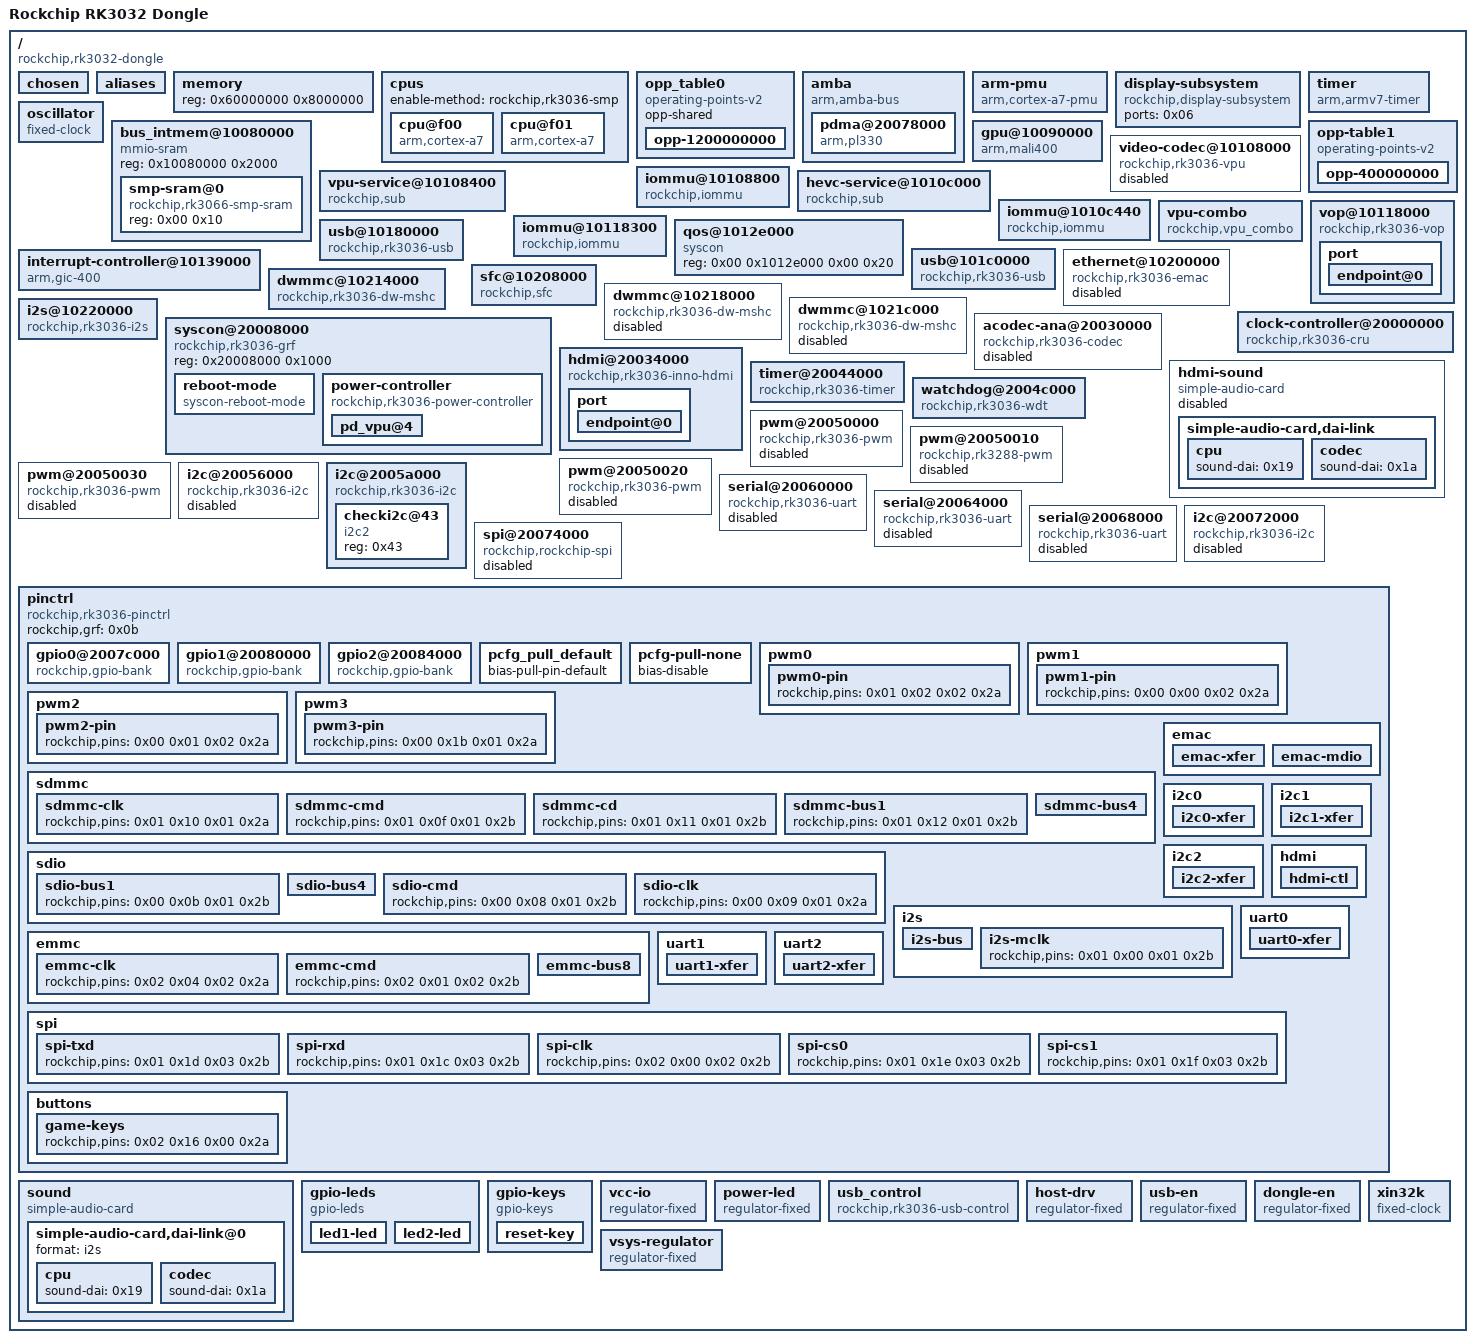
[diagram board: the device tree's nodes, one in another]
/dts-v1/;

/ {
	#address-cells = <0x01>;
	#size-cells = <0x01>;
	compatible = "rockchip,rk3032-dongle\0rockchip,rk3036";
	interrupt-parent = <0x01>;
	model = "Rockchip RK3032 Dongle";

	chosen {
		bootargs = "console=ttyS0,115200 rw root=PARTUUID=614e0000-0000 rootfstype=squashfs rootwait";
	};

	aliases {
		ethernet0 = "/ethernet@10200000";
		i2c0 = "/i2c@20072000";
		i2c1 = "/i2c@20056000";
		i2c2 = "/i2c@2005a000";
		mshc0 = "/dwmmc@1021c000";
		mshc1 = "/dwmmc@10214000";
		mshc2 = "/dwmmc@10218000";
		serial0 = "/serial@20060000";
		serial1 = "/serial@20064000";
		serial2 = "/serial@20068000";
		spi = "/spi@20074000";
	};

	memory {
		device_type = "memory";
		reg = <0x60000000 0x8000000>;
	};

	cpus {
		#address-cells = <0x01>;
		#size-cells = <0x00>;
		enable-method = "rockchip,rk3036-smp";

		cpu@f00 {
			device_type = "cpu";
			compatible = "arm,cortex-a7";
			reg = <0xf00>;
			resets = <0x02 0x00>;
			operating-points-v2 = <0x03>;
			clocks = <0x02 0x04>;
			phandle = <0x04>;
		};

		cpu@f01 {
			device_type = "cpu";
			compatible = "arm,cortex-a7";
			reg = <0xf01>;
			resets = <0x02 0x01>;
			operating-points-v2 = <0x03>;
			phandle = <0x05>;
		};
	};

	opp_table0 {
		compatible = "operating-points-v2";
		opp-shared;
		phandle = <0x03>;

		opp-1200000000 {
			opp-hz = <0x00 0x47868c00>;
			opp-microvolt = <0x12b128 0x12b128 0x12b128>;
			clock-latency-ns = <0x9c40>;
		};
	};

	amba {
		compatible = "arm,amba-bus";
		#address-cells = <0x01>;
		#size-cells = <0x01>;
		ranges;

		pdma@20078000 {
			compatible = "arm,pl330\0arm,primecell";
			reg = <0x20078000 0x4000>;
			interrupts = <0x00 0x00 0x04 0x00 0x01 0x04>;
			#dma-cells = <0x01>;
			arm,pl330-broken-no-flushp;
			peripherals-req-type-burst;
			clocks = <0x02 0xc2>;
			clock-names = "apb_pclk";
			phandle = <0x13>;
		};
	};

	arm-pmu {
		compatible = "arm,cortex-a7-pmu";
		interrupts = <0x00 0x4c 0x04 0x00 0x4d 0x04>;
		interrupt-affinity = <0x04 0x05>;
	};

	display-subsystem {
		compatible = "rockchip,display-subsystem";
		ports = <0x06>;
	};

	timer {
		compatible = "arm,armv7-timer";
		arm,cpu-registers-not-fw-configured;
		interrupts = <0x01 0x0d 0x304 0x01 0x0e 0x304 0x01 0x0b 0x304 0x01 0x0a 0x304>;
		clock-frequency = <0x16e3600>;
	};

	oscillator {
		compatible = "fixed-clock";
		clock-frequency = <0x16e3600>;
		clock-output-names = "xin24m";
		#clock-cells = <0x00>;
		phandle = <0x1b>;
	};

	bus_intmem@10080000 {
		compatible = "mmio-sram";
		reg = <0x10080000 0x2000>;
		#address-cells = <0x01>;
		#size-cells = <0x01>;
		ranges = <0x00 0x10080000 0x2000>;

		smp-sram@0 {
			compatible = "rockchip,rk3066-smp-sram";
			reg = <0x00 0x10>;
		};
	};

	gpu@10090000 {
		compatible = "arm,mali400";
		reg = <0x10091000 0x200 0x10090000 0x100 0x10093000 0x100 0x10098000 0x1100 0x10094000 0x100>;
		reg-names = "Mali_L2\0Mali_GP\0Mali_GP_MMU\0Mali_PP0\0Mali_PP0_MMU";
		interrupts = <0x00 0x03 0x04 0x00 0x04 0x04 0x00 0x05 0x04 0x00 0x04 0x04>;
		interrupt-names = "Mali_GP_IRQ\0Mali_GP_MMU_IRQ\0Mali_PP0_IRQ\0Mali_PP0_MMU_IRQ";
		clocks = <0x02 0x40>;
		clock-names = "clk_mali";
		assigned-clocks = <0x02 0x40>;
		assigned-clock-rates = <0x17d78400>;
		assigned-clock-parents = <0x02 0x02>;
		operating-points-v2 = <0x07>;
		status = "okay";
		phandle = <0x2f>;
	};

	opp-table1 {
		compatible = "operating-points-v2";
		phandle = <0x07>;

		opp-400000000 {
			opp-hz = <0x00 0x17d78400>;
			opp-microvolt = <0x10c8e0>;
		};
	};

	video-codec@10108000 {
		compatible = "rockchip,rk3036-vpu\0rockchip,rk3288-vpu";
		reg = <0x10108000 0x800>;
		interrupts = <0x00 0x06 0x04 0x00 0x07 0x04>;
		interrupt-names = "vepu\0vdpu";
		clocks = <0x02 0xd0 0x02 0x1dc>;
		clock-names = "aclk\0hclk";
		iommus = <0x08>;
		assigned-clocks = <0x02 0xd0>;
		assigned-clock-rates = <0x11b3dc40>;
		assigned-clock-parents = <0x02 0x03>;
		power-domains = <0x09 0x04>;
		status = "disabled";
		phandle = <0x30>;
	};

	vpu-service@10108400 {
		compatible = "rockchip,sub";
		reg = <0x10108400 0x400>;
		dev_mode = <0x00>;
		interrupts = <0x00 0x07 0x04>;
		interrupt-names = "irq_dec";
		iommus = <0x08>;
		allocator = <0x01>;
		power-domains = <0x09 0x04>;
		phandle = <0x0d>;
	};

	iommu@10108800 {
		compatible = "rockchip,iommu";
		reg = <0x10108800 0x100>;
		interrupts = <0x00 0x37 0x04>;
		interrupt-names = "vpu_mmu";
		#iommu-cells = <0x00>;
		power-domains = <0x09 0x04>;
		status = "okay";
		phandle = <0x08>;
	};

	hevc-service@1010c000 {
		compatible = "rockchip,sub";
		reg = <0x1010c000 0x400>;
		dev_mode = <0x01>;
		interrupts = <0x00 0x39 0x04>;
		interrupt-names = "irq_dec";
		allocator = <0x01>;
		iommus = <0x0a>;
		power-domains = <0x09 0x04>;
		phandle = <0x0c>;
	};

	iommu@1010c440 {
		compatible = "rockchip,iommu";
		reg = <0x1010c440 0x40 0x1010c480 0x40>;
		interrupts = <0x00 0x38 0x04>;
		interrupt-names = "hevc_mmu";
		#iommu-cells = <0x00>;
		power-domains = <0x09 0x04>;
		status = "okay";
		phandle = <0x0a>;
	};

	vpu-combo {
		compatible = "rockchip,vpu_combo";
		rockchip,grf = <0x0b>;
		subcnt = <0x02>;
		rockchip,sub = <0x0c 0x0d>;
		mode_bit = <0x03>;
		mode_ctrl = <0x144>;
		clocks = <0x02 0xd0 0x02 0x1dc 0x02 0xd3>;
		clock-names = "aclk_vcodec\0hclk_vcodec\0clk_core";
		assigned-clocks = <0x02 0xd0>;
		assigned-clock-rates = <0x11b3dc40>;
		assigned-clock-parents = <0x02 0x03>;
		resets = <0x02 0x70 0x02 0x71 0x02 0x73>;
		reset-names = "video_a\0video_h\0video";
		power-domains = <0x09 0x04>;
		status = "okay";
		phandle = <0x31>;
	};

	vop@10118000 {
		compatible = "rockchip,rk3036-vop";
		reg = <0x10118000 0x19c>;
		interrupts = <0x00 0x2b 0x04>;
		clocks = <0x02 0xc5 0x02 0x64 0x02 0x1d1>;
		clock-names = "aclk_vop\0dclk_vop\0hclk_vop";
		resets = <0x02 0x75 0x02 0x76 0x02 0x77>;
		reset-names = "axi\0ahb\0dclk";
		iommus = <0x0e>;
		status = "okay";
		phandle = <0x32>;

		port {
			#address-cells = <0x01>;
			#size-cells = <0x00>;
			phandle = <0x06>;

			endpoint@0 {
				reg = <0x00>;
				remote-endpoint = <0x0f>;
				phandle = <0x18>;
			};
		};
	};

	iommu@10118300 {
		compatible = "rockchip,iommu";
		reg = <0x10118300 0x100>;
		interrupts = <0x00 0x2b 0x04>;
		interrupt-names = "vop_mmu";
		#iommu-cells = <0x00>;
		status = "okay";
		phandle = <0x0e>;
	};

	qos@1012e000 {
		compatible = "syscon";
		reg = <0x00 0x1012e000 0x00 0x20>;
		phandle = <0x16>;
	};

	interrupt-controller@10139000 {
		compatible = "arm,gic-400";
		interrupt-controller;
		#interrupt-cells = <0x03>;
		#address-cells = <0x00>;
		reg = <0x10139000 0x1000 0x1013a000 0x2000 0x1013c000 0x2000 0x1013e000 0x2000>;
		interrupts = <0x01 0x09 0x304>;
		phandle = <0x01>;
	};

	usb@10180000 {
		compatible = "rockchip,rk3036-usb\0rockchip,rk3066-usb\0snps,dwc2";
		reg = <0x10180000 0x40000>;
		interrupts = <0x00 0x0a 0x04>;
		clocks = <0x02 0x1c1>;
		clock-names = "otg";
		dr_mode = "host";
		g-np-tx-fifo-size = <0x10>;
		g-rx-fifo-size = <0x118>;
		g-tx-fifo-size = <0x100 0x80 0x80 0x40 0x20 0x10>;
		g-use-dma;
		status = "okay";
		phandle = <0x33>;
	};

	usb@101c0000 {
		compatible = "rockchip,rk3036-usb\0rockchip,rk3066-usb\0snps,dwc2";
		reg = <0x101c0000 0x40000>;
		interrupts = <0x00 0x0b 0x04>;
		clocks = <0x02 0x1c2>;
		clock-names = "otg";
		dr_mode = "host";
		status = "okay";
		phandle = <0x34>;
	};

	ethernet@10200000 {
		compatible = "rockchip,rk3036-emac\0snps,arc-emac";
		reg = <0x10200000 0x4000>;
		interrupts = <0x00 0x08 0x04>;
		#address-cells = <0x01>;
		#size-cells = <0x00>;
		rockchip,grf = <0x0b>;
		clocks = <0x02 0x1cc 0x02 0x98 0x02 0x97>;
		clock-names = "hclk\0macref\0macclk";
		assigned-clocks = <0x02 0x99>;
		assigned-clock-parents = <0x02 0x02>;
		max-speed = <0x64>;
		phy-mode = "rmii";
		status = "disabled";
		phandle = <0x35>;
	};

	sfc@10208000 {
		compatible = "rockchip,sfc";
		reg = <0x10208000 0x200>;
		interrupts = <0x00 0x09 0x04>;
		clocks = <0x02 0xa0 0x02 0x1c6>;
		clock-names = "clk_sfc\0hclk_sfc";
		assigned-clocks = <0x02 0xa0>;
		assigned-clock-rates = <0x5f5e100>;
		status = "okay";
		phandle = <0x36>;
	};

	dwmmc@10214000 {
		compatible = "rockchip,rk3036-dw-mshc\0rockchip,rk3288-dw-mshc";
		reg = <0x10214000 0x4000>;
		interrupts = <0x00 0x0e 0x04>;
		#address-cells = <0x01>;
		#size-cells = <0x00>;
		pinctrl-names = "default";
		pinctrl-0 = <0x10 0x11 0x12>;
		clock-freq-min-max = <0x61a80 0x23c3460>;
		clocks = <0x02 0x1c8 0x02 0x44>;
		clock-names = "biu\0ciu";
		dmas = <0x13 0x0a>;
		dma-names = "rx-tx";
		num-slots = <0x01>;
		fifo-depth = <0x100>;
		bus-width = <0x04>;
		status = "okay";
		clock-frequency = <0x23c3460>;
		supports-highspeed;
		supports-sd;
		broken-cd;
		card-detect-delay = <0xc8>;
		ignore-pm-notify;
		keep-power-in-suspend;
		vmmc-supply = <0x14>;
		cd-gpios = <0x15 0x11 0x00>;
		phandle = <0x37>;
	};

	dwmmc@10218000 {
		compatible = "rockchip,rk3036-dw-mshc\0rockchip,rk3288-dw-mshc";
		reg = <0x10218000 0x4000>;
		clock-freq-min-max = <0x61a80 0x23c3460>;
		clocks = <0x02 0x1c9 0x02 0x45 0x02 0x73 0x02 0x77>;
		clock-names = "biu\0ciu\0ciu_drv\0ciu_sample";
		fifo-depth = <0x100>;
		interrupts = <0x00 0x0f 0x04>;
		status = "disabled";
		phandle = <0x38>;
	};

	dwmmc@1021c000 {
		compatible = "rockchip,rk3036-dw-mshc\0rockchip,rk3288-dw-mshc";
		reg = <0x1021c000 0x4000>;
		interrupts = <0x00 0x10 0x04>;
		bus-width = <0x08>;
		cap-mmc-highspeed;
		clock-frequency = <0x23c3460>;
		clock-freq-min-max = <0x61a80 0x23c3460>;
		clocks = <0x02 0x1cb 0x02 0x47 0x02 0x75 0x02 0x79>;
		clock-names = "biu\0ciu\0ciu_drv\0ciu_sample";
		default-sample-phase = <0x9e>;
		disable-wp;
		dmas = <0x13 0x0c>;
		dma-names = "rx-tx";
		fifo-depth = <0x100>;
		non-removable;
		num-slots = <0x01>;
		supports-emmc;
		status = "disabled";
		phandle = <0x39>;
	};

	i2s@10220000 {
		compatible = "rockchip,rk3036-i2s\0rockchip,rk3066-i2s";
		reg = <0x10220000 0x4000>;
		interrupts = <0x00 0x33 0x04>;
		#address-cells = <0x01>;
		#size-cells = <0x00>;
		clock-names = "i2s_clk\0i2s_hclk";
		clocks = <0x02 0x52 0x02 0x1ce>;
		assigned-clocks = <0x02 0x7f>;
		assigned-clock-parents = <0x02 0x7e>;
		dmas = <0x13 0x00 0x13 0x01>;
		dma-names = "tx\0rx";
		resets = <0x02 0x18>;
		reset-names = "reset-m";
		status = "okay";
		#sound-dai-cells = <0x00>;
		phandle = <0x19>;
	};

	clock-controller@20000000 {
		compatible = "rockchip,rk3036-cru";
		reg = <0x20000000 0x1000>;
		rockchip,grf = <0x0b>;
		#clock-cells = <0x01>;
		#reset-cells = <0x01>;
		assigned-clocks = <0x02 0x03>;
		assigned-clock-rates = <0x2367b880>;
		phandle = <0x02>;
	};

	syscon@20008000 {
		compatible = "rockchip,rk3036-grf\0syscon\0simple-mfd";
		reg = <0x20008000 0x1000>;
		phandle = <0x0b>;

		reboot-mode {
			compatible = "syscon-reboot-mode";
			offset = <0x1d8>;
			mode-normal = <0x5242c300>;
			mode-recovery = <0x5242c303>;
			mode-bootloader = <0x5242c309>;
			mode-loader = <0x5242c301>;
			mode-ums = <0x5242c30c>;
		};

		power-controller {
			compatible = "rockchip,rk3036-power-controller";
			#power-domain-cells = <0x01>;
			#address-cells = <0x01>;
			#size-cells = <0x00>;
			phandle = <0x09>;

			pd_vpu@4 {
				reg = <0x04>;
				clocks = <0x02 0xd0 0x02 0x1dc 0x02 0xd3>;
				pm_qos = <0x16>;
			};
		};
	};

	acodec-ana@20030000 {
		compatible = "rockchip,rk3036-codec";
		reg = <0x20030000 0x4000>;
		rockchip,grf = <0x0b>;
		clock-names = "acodec_pclk";
		clocks = <0x02 0x171>;
		#sound-dai-cells = <0x00>;
		status = "disabled";
		phandle = <0x3a>;
	};

	hdmi@20034000 {
		compatible = "rockchip,rk3036-inno-hdmi";
		reg = <0x20034000 0x4000>;
		interrupts = <0x00 0x2d 0x04>;
		clocks = <0x02 0xcb 0x02 0x168>;
		clock-names = "aclk\0pclk";
		rockchip,grf = <0x0b>;
		pinctrl-names = "default";
		pinctrl-0 = <0x17>;
		#address-cells = <0x01>;
		#size-cells = <0x00>;
		#sound-dai-cells = <0x00>;
		status = "okay";
		phandle = <0x1a>;

		port {
			#address-cells = <0x01>;
			#size-cells = <0x00>;
			phandle = <0x3b>;

			endpoint@0 {
				reg = <0x00>;
				remote-endpoint = <0x18>;
				phandle = <0x0f>;
			};
		};
	};

	hdmi-sound {
		compatible = "simple-audio-card";
		simple-audio-card,name = "rockchip,hdmi";
		simple-audio-card,widgets = "Headphone\0Out Jack\0Line\0In Jack";
		status = "disabled";
		phandle = <0x3c>;

		simple-audio-card,dai-link {
			format = "i2s";
			mclk-fs = <0x100>;

			cpu {
				sound-dai = <0x19>;
			};

			codec {
				sound-dai = <0x1a>;
			};
		};
	};

	timer@20044000 {
		compatible = "rockchip,rk3036-timer\0rockchip,rk3288-timer";
		reg = <0x20044000 0x20>;
		interrupts = <0x00 0x1c 0x04>;
		clocks = <0x1b 0x02 0x161>;
		clock-names = "timer\0pclk";
		phandle = <0x3d>;
	};

	watchdog@2004c000 {
		compatible = "rockchip,rk3036-wdt\0snps,dw-wdt";
		reg = <0x2004c000 0x100>;
		clocks = <0x02 0x170>;
		status = "okay";
		phandle = <0x3e>;
	};

	pwm@20050000 {
		compatible = "rockchip,rk3036-pwm\0rockchip,rk2928-pwm";
		reg = <0x20050000 0x10>;
		#pwm-cells = <0x03>;
		clocks = <0x02 0x15e>;
		clock-names = "pwm";
		pinctrl-names = "active";
		pinctrl-0 = <0x1c>;
		status = "disabled";
		phandle = <0x3f>;
	};

	pwm@20050010 {
		compatible = "rockchip,rk3288-pwm";
		reg = <0x20050010 0x10>;
		#pwm-cells = <0x03>;
		clocks = <0x02 0x15e>;
		clock-names = "pwm";
		pinctrl-names = "active";
		pinctrl-0 = <0x1d>;
		status = "disabled";
		phandle = <0x40>;
	};

	pwm@20050020 {
		compatible = "rockchip,rk3036-pwm\0rockchip,rk2928-pwm";
		reg = <0x20050020 0x10>;
		#pwm-cells = <0x03>;
		clocks = <0x02 0x15e>;
		clock-names = "pwm";
		pinctrl-names = "active";
		pinctrl-0 = <0x1e>;
		status = "disabled";
		phandle = <0x41>;
	};

	pwm@20050030 {
		compatible = "rockchip,rk3036-pwm\0rockchip,rk2928-pwm";
		reg = <0x20050030 0x10>;
		#pwm-cells = <0x02>;
		clocks = <0x02 0x15e>;
		clock-names = "pwm";
		pinctrl-names = "active";
		pinctrl-0 = <0x1f>;
		status = "disabled";
		phandle = <0x42>;
	};

	i2c@20056000 {
		compatible = "rockchip,rk3036-i2c\0rockchip,rk3288-i2c";
		reg = <0x20056000 0x1000>;
		interrupts = <0x00 0x19 0x04>;
		#address-cells = <0x01>;
		#size-cells = <0x00>;
		clock-names = "i2c";
		clocks = <0x02 0x14d>;
		pinctrl-names = "default";
		pinctrl-0 = <0x20>;
		status = "disabled";
		phandle = <0x43>;
	};

	i2c@2005a000 {
		compatible = "rockchip,rk3036-i2c\0rockchip,rk3288-i2c";
		reg = <0x2005a000 0x1000>;
		interrupts = <0x00 0x1a 0x04>;
		#address-cells = <0x01>;
		#size-cells = <0x00>;
		clock-names = "i2c";
		clocks = <0x02 0x14e>;
		pinctrl-names = "default";
		pinctrl-0 = <0x21>;
		status = "okay";
		clock-frequency = <0xc350>;
		phandle = <0x44>;

		checki2c@43 {
			compatible = "i2c2";
			reg = <0x43>;
		};
	};

	serial@20060000 {
		compatible = "rockchip,rk3036-uart\0snps,dw-apb-uart";
		reg = <0x20060000 0x100>;
		interrupts = <0x00 0x14 0x04>;
		reg-shift = <0x02>;
		reg-io-width = <0x04>;
		clock-frequency = <0x16e3600>;
		clocks = <0x02 0x4d 0x02 0x155>;
		clock-names = "baudclk\0apb_pclk";
		pinctrl-names = "default";
		pinctrl-0 = <0x22>;
		status = "disabled";
		phandle = <0x45>;
	};

	serial@20064000 {
		compatible = "rockchip,rk3036-uart\0snps,dw-apb-uart";
		reg = <0x20064000 0x100>;
		interrupts = <0x00 0x15 0x04>;
		reg-shift = <0x02>;
		reg-io-width = <0x04>;
		clock-frequency = <0x16e3600>;
		clocks = <0x02 0x4e 0x02 0x156>;
		clock-names = "baudclk\0apb_pclk";
		pinctrl-names = "default";
		pinctrl-0 = <0x23>;
		status = "disabled";
		phandle = <0x46>;
	};

	serial@20068000 {
		compatible = "rockchip,rk3036-uart\0snps,dw-apb-uart";
		reg = <0x20068000 0x100>;
		interrupts = <0x00 0x16 0x04>;
		reg-shift = <0x02>;
		reg-io-width = <0x04>;
		clock-frequency = <0x16e3600>;
		clocks = <0x02 0x4f 0x02 0x157>;
		clock-names = "baudclk\0apb_pclk";
		pinctrl-names = "default";
		pinctrl-0 = <0x24>;
		status = "disabled";
		phandle = <0x47>;
	};

	i2c@20072000 {
		compatible = "rockchip,rk3036-i2c\0rockchip,rk3288-i2c";
		reg = <0x20072000 0x1000>;
		interrupts = <0x00 0x18 0x04>;
		#address-cells = <0x01>;
		#size-cells = <0x00>;
		clock-names = "i2c";
		clocks = <0x02 0x14c>;
		pinctrl-names = "default";
		pinctrl-0 = <0x25>;
		status = "disabled";
		phandle = <0x48>;
	};

	spi@20074000 {
		compatible = "rockchip,rockchip-spi";
		reg = <0x20074000 0x1000>;
		interrupts = <0x00 0x17 0x04>;
		clocks = <0x02 0x152 0x02 0x41>;
		clock-names = "apb-pclk\0spi_pclk";
		dmas = <0x13 0x08 0x13 0x09>;
		dma-names = "tx\0rx";
		pinctrl-names = "default";
		pinctrl-0 = <0x26 0x27 0x28 0x29>;
		#address-cells = <0x01>;
		#size-cells = <0x00>;
		status = "disabled";
		phandle = <0x49>;
	};

	pinctrl {
		compatible = "rockchip,rk3036-pinctrl";
		rockchip,grf = <0x0b>;
		#address-cells = <0x01>;
		#size-cells = <0x01>;
		ranges;
		phandle = <0x4a>;

		gpio0@2007c000 {
			compatible = "rockchip,gpio-bank";
			reg = <0x2007c000 0x100>;
			interrupts = <0x00 0x24 0x04>;
			clocks = <0x02 0x140>;
			gpio-controller;
			#gpio-cells = <0x02>;
			interrupt-controller;
			#interrupt-cells = <0x02>;
			phandle = <0x2e>;
		};

		gpio1@20080000 {
			compatible = "rockchip,gpio-bank";
			reg = <0x20080000 0x100>;
			interrupts = <0x00 0x25 0x04>;
			clocks = <0x02 0x141>;
			gpio-controller;
			#gpio-cells = <0x02>;
			interrupt-controller;
			#interrupt-cells = <0x02>;
			phandle = <0x15>;
		};

		gpio2@20084000 {
			compatible = "rockchip,gpio-bank";
			reg = <0x20084000 0x100>;
			interrupts = <0x00 0x26 0x04>;
			clocks = <0x02 0x142>;
			gpio-controller;
			#gpio-cells = <0x02>;
			interrupt-controller;
			#interrupt-cells = <0x02>;
			phandle = <0x2d>;
		};

		pcfg_pull_default {
			bias-pull-pin-default;
			phandle = <0x2b>;
		};

		pcfg-pull-none {
			bias-disable;
			phandle = <0x2a>;
		};

		pwm0 {

			pwm0-pin {
				rockchip,pins = <0x01 0x02 0x02 0x2a>;
				phandle = <0x1c>;
			};
		};

		pwm1 {

			pwm1-pin {
				rockchip,pins = <0x00 0x00 0x02 0x2a>;
				phandle = <0x1d>;
			};
		};

		pwm2 {

			pwm2-pin {
				rockchip,pins = <0x00 0x01 0x02 0x2a>;
				phandle = <0x1e>;
			};
		};

		pwm3 {

			pwm3-pin {
				rockchip,pins = <0x00 0x1b 0x01 0x2a>;
				phandle = <0x1f>;
			};
		};

		sdmmc {

			sdmmc-clk {
				rockchip,pins = <0x01 0x10 0x01 0x2a>;
				phandle = <0x10>;
			};

			sdmmc-cmd {
				rockchip,pins = <0x01 0x0f 0x01 0x2b>;
				phandle = <0x11>;
			};

			sdmmc-cd {
				rockchip,pins = <0x01 0x11 0x01 0x2b>;
				phandle = <0x4b>;
			};

			sdmmc-bus1 {
				rockchip,pins = <0x01 0x12 0x01 0x2b>;
				phandle = <0x4c>;
			};

			sdmmc-bus4 {
				rockchip,pins = <0x01 0x12 0x01 0x2b 0x01 0x13 0x01 0x2b 0x01 0x14 0x01 0x2b 0x01 0x15 0x01 0x2b>;
				phandle = <0x12>;
			};
		};

		sdio {

			sdio-bus1 {
				rockchip,pins = <0x00 0x0b 0x01 0x2b>;
				phandle = <0x4d>;
			};

			sdio-bus4 {
				rockchip,pins = <0x00 0x0b 0x01 0x2b 0x00 0x0c 0x01 0x2b 0x00 0x0d 0x01 0x2b 0x00 0x0e 0x01 0x2b>;
				phandle = <0x4e>;
			};

			sdio-cmd {
				rockchip,pins = <0x00 0x08 0x01 0x2b>;
				phandle = <0x4f>;
			};

			sdio-clk {
				rockchip,pins = <0x00 0x09 0x01 0x2a>;
				phandle = <0x50>;
			};
		};

		emmc {

			emmc-clk {
				rockchip,pins = <0x02 0x04 0x02 0x2a>;
				phandle = <0x51>;
			};

			emmc-cmd {
				rockchip,pins = <0x02 0x01 0x02 0x2b>;
				phandle = <0x52>;
			};

			emmc-bus8 {
				rockchip,pins = <0x01 0x18 0x02 0x2b 0x01 0x19 0x02 0x2b 0x01 0x1a 0x02 0x2b 0x01 0x1b 0x02 0x2b 0x01 0x1c 0x02 0x2b 0x01 0x1d 0x02 0x2b 0x01 0x1e 0x02 0x2b 0x01 0x1f 0x02 0x2b>;
				phandle = <0x53>;
			};
		};

		emac {

			emac-xfer {
				rockchip,pins = <0x02 0x0a 0x01 0x2b 0x02 0x0d 0x01 0x2b 0x02 0x0e 0x01 0x2b 0x02 0x0f 0x01 0x2b 0x02 0x10 0x01 0x2b 0x02 0x11 0x01 0x2b 0x02 0x12 0x01 0x2b 0x02 0x13 0x01 0x2b>;
				phandle = <0x54>;
			};

			emac-mdio {
				rockchip,pins = <0x02 0x0c 0x01 0x2b 0x02 0x19 0x01 0x2b>;
				phandle = <0x55>;
			};
		};

		i2c0 {

			i2c0-xfer {
				rockchip,pins = <0x00 0x00 0x01 0x2a 0x00 0x01 0x01 0x2a>;
				phandle = <0x25>;
			};
		};

		i2c1 {

			i2c1-xfer {
				rockchip,pins = <0x00 0x02 0x01 0x2a 0x00 0x03 0x01 0x2a>;
				phandle = <0x20>;
			};
		};

		i2c2 {

			i2c2-xfer {
				rockchip,pins = <0x02 0x14 0x01 0x2a 0x02 0x15 0x01 0x2a>;
				phandle = <0x21>;
			};
		};

		i2s {

			i2s-bus {
				rockchip,pins = <0x01 0x01 0x01 0x2b 0x01 0x02 0x01 0x2b 0x01 0x03 0x01 0x2b 0x01 0x04 0x01 0x2b 0x01 0x05 0x01 0x2b>;
				phandle = <0x56>;
			};

			i2s-mclk {
				rockchip,pins = <0x01 0x00 0x01 0x2b>;
				phandle = <0x57>;
			};
		};

		hdmi {

			hdmi-ctl {
				rockchip,pins = <0x01 0x08 0x01 0x2a 0x01 0x09 0x01 0x2a 0x01 0x0a 0x01 0x2a 0x01 0x0b 0x01 0x2a>;
				phandle = <0x17>;
			};
		};

		uart0 {

			uart0-xfer {
				rockchip,pins = <0x00 0x10 0x01 0x2b 0x00 0x11 0x01 0x2a>;
				phandle = <0x22>;
			};
		};

		uart1 {

			uart1-xfer {
				rockchip,pins = <0x02 0x16 0x01 0x2b 0x02 0x17 0x01 0x2a>;
				phandle = <0x23>;
			};
		};

		uart2 {

			uart2-xfer {
				rockchip,pins = <0x01 0x12 0x02 0x2b 0x01 0x13 0x02 0x2a>;
				phandle = <0x24>;
			};
		};

		spi {

			spi-txd {
				rockchip,pins = <0x01 0x1d 0x03 0x2b>;
				phandle = <0x26>;
			};

			spi-rxd {
				rockchip,pins = <0x01 0x1c 0x03 0x2b>;
				phandle = <0x27>;
			};

			spi-clk {
				rockchip,pins = <0x02 0x00 0x02 0x2b>;
				phandle = <0x28>;
			};

			spi-cs0 {
				rockchip,pins = <0x01 0x1e 0x03 0x2b>;
				phandle = <0x29>;
			};

			spi-cs1 {
				rockchip,pins = <0x01 0x1f 0x03 0x2b>;
				phandle = <0x58>;
			};
		};

		buttons {

			game-keys {
				rockchip,pins = <0x02 0x16 0x00 0x2a>;
				phandle = <0x2c>;
			};
		};
	};

	sound {
		compatible = "simple-audio-card";
		simple-audio-card,format = "i2s";
		simple-audio-card,name = "rockchip,hdmi";
		simple-audio-card,mclk-fs = <0x100>;

		simple-audio-card,dai-link@0 {
			format = "i2s";

			cpu {
				sound-dai = <0x19>;
			};

			codec {
				sound-dai = <0x1a>;
			};
		};
	};

	gpio-leds {
		compatible = "gpio-leds";
		phandle = <0x59>;

		led1-led {
			label = "Breathing_led1";
			gpios = <0x15 0x01 0x00>;
			linux,default-trigger = "default-on";
		};

		led2-led {
			label = "Breathing_led2";
			gpios = <0x15 0x00 0x00>;
			linux,default-trigger = "default-on";
		};
	};

	gpio-keys {
		compatible = "gpio-keys";
		autorepeat;
		pinctrl-names = "default";
		pinctrl-0 = <0x2c>;

		reset-key {
			gpios = <0x2d 0x16 0x01>;
			linux,code = <0x66>;
			label = "GPIO Key Home";
			debounce-interval = <0x14>;
		};
	};

	vcc-io {
		compatible = "regulator-fixed";
		regulator-name = "vcc_io";
		regulator-min-microvolt = <0x325aa0>;
		regulator-max-microvolt = <0x325aa0>;
		regulator-always-on;
		regulator-boot-on;
		phandle = <0x14>;
	};

	power-led {
		compatible = "regulator-fixed";
		gpio = <0x2d 0x17 0x00>;
		regulator-name = "power_led";
		enable-active-high;
		regulator-min-microvolt = <0x325aa0>;
		regulator-max-microvolt = <0x325aa0>;
		regulator-always-on;
		regulator-boot-on;
		phandle = <0x5a>;
	};

	usb_control {
		compatible = "rockchip,rk3036-usb-control";
		rockchip,grf = <0x0b>;
		rockchip,remote_wakeup;
		rockchip,usb_irq_wakeup;
	};

	host-drv {
		compatible = "regulator-fixed";
		gpio = <0x2e 0x13 0x00>;
		regulator-name = "host_drv";
		enable-active-high;
		regulator-min-microvolt = <0x4c4b40>;
		regulator-max-microvolt = <0x4c4b40>;
		regulator-always-on;
		regulator-boot-on;
		phandle = <0x5b>;
	};

	usb-en {
		compatible = "regulator-fixed";
		gpio = <0x2d 0x1e 0x00>;
		regulator-name = "usb_en";
		enable-active-high;
		regulator-min-microvolt = <0x325aa0>;
		regulator-max-microvolt = <0x325aa0>;
		regulator-always-on;
		regulator-boot-on;
		phandle = <0x5c>;
	};

	dongle-en {
		compatible = "regulator-fixed";
		gpio = <0x2d 0x0b 0x00>;
		regulator-name = "dongle_en";
		enable-active-high;
		enable-active-low;
		regulator-min-microvolt = <0x325aa0>;
		regulator-max-microvolt = <0x325aa0>;
		regulator-always-on;
		regulator-boot-on;
		phandle = <0x5d>;
	};

	vsys-regulator {
		compatible = "regulator-fixed";
		regulator-name = "vcc_sys";
		regulator-min-microvolt = <0x4c4b40>;
		regulator-max-microvolt = <0x4c4b40>;
		regulator-always-on;
		regulator-boot-on;
		phandle = <0x5e>;
	};

	xin32k {
		compatible = "fixed-clock";
		clock-frequency = <0x8000>;
		clock-output-names = "xin32k";
		#clock-cells = <0x00>;
		phandle = <0x5f>;
	};

	__symbols__ {
		cpu0 = "/cpus/cpu@f00";
		cpu1 = "/cpus/cpu@f01";
		cpu0_opp_table = "/opp_table0";
		pdma = "/amba/pdma@20078000";
		xin24m = "/oscillator";
		gpu = "/gpu@10090000";
		gpu_opp_table = "/opp-table1";
		vpu = "/video-codec@10108000";
		vpu_service = "/vpu-service@10108400";
		vpu_mmu = "/iommu@10108800";
		hevc_service = "/hevc-service@1010c000";
		hevc_mmu = "/iommu@1010c440";
		vpu_combo = "/vpu-combo";
		vop = "/vop@10118000";
		vop_out = "/vop@10118000/port";
		vop_out_hdmi = "/vop@10118000/port/endpoint@0";
		vop_mmu = "/iommu@10118300";
		qos_vpu = "/qos@1012e000";
		gic = "/interrupt-controller@10139000";
		usb_otg = "/usb@10180000";
		usb_host = "/usb@101c0000";
		emac = "/ethernet@10200000";
		sfc = "/sfc@10208000";
		sdmmc = "/dwmmc@10214000";
		sdio = "/dwmmc@10218000";
		emmc = "/dwmmc@1021c000";
		i2s = "/i2s@10220000";
		cru = "/clock-controller@20000000";
		grf = "/syscon@20008000";
		power = "/syscon@20008000/power-controller";
		acodec = "/acodec-ana@20030000";
		hdmi = "/hdmi@20034000";
		hdmi_in = "/hdmi@20034000/port";
		hdmi_in_vop = "/hdmi@20034000/port/endpoint@0";
		hdmi_sound = "/hdmi-sound";
		timer = "/timer@20044000";
		wdt = "/watchdog@2004c000";
		pwm0 = "/pwm@20050000";
		pwm1 = "/pwm@20050010";
		pwm2 = "/pwm@20050020";
		pwm3 = "/pwm@20050030";
		i2c1 = "/i2c@20056000";
		i2c2 = "/i2c@2005a000";
		uart0 = "/serial@20060000";
		uart1 = "/serial@20064000";
		uart2 = "/serial@20068000";
		i2c0 = "/i2c@20072000";
		spi = "/spi@20074000";
		pinctrl = "/pinctrl";
		gpio0 = "/pinctrl/gpio0@2007c000";
		gpio1 = "/pinctrl/gpio1@20080000";
		gpio2 = "/pinctrl/gpio2@20084000";
		pcfg_pull_default = "/pinctrl/pcfg_pull_default";
		pcfg_pull_none = "/pinctrl/pcfg-pull-none";
		pwm0_pin = "/pinctrl/pwm0/pwm0-pin";
		pwm1_pin = "/pinctrl/pwm1/pwm1-pin";
		pwm2_pin = "/pinctrl/pwm2/pwm2-pin";
		pwm3_pin = "/pinctrl/pwm3/pwm3-pin";
		sdmmc_clk = "/pinctrl/sdmmc/sdmmc-clk";
		sdmmc_cmd = "/pinctrl/sdmmc/sdmmc-cmd";
		sdmmc_cd = "/pinctrl/sdmmc/sdmmc-cd";
		sdmmc_bus1 = "/pinctrl/sdmmc/sdmmc-bus1";
		sdmmc_bus4 = "/pinctrl/sdmmc/sdmmc-bus4";
		sdio_bus1 = "/pinctrl/sdio/sdio-bus1";
		sdio_bus4 = "/pinctrl/sdio/sdio-bus4";
		sdio_cmd = "/pinctrl/sdio/sdio-cmd";
		sdio_clk = "/pinctrl/sdio/sdio-clk";
		emmc_clk = "/pinctrl/emmc/emmc-clk";
		emmc_cmd = "/pinctrl/emmc/emmc-cmd";
		emmc_bus8 = "/pinctrl/emmc/emmc-bus8";
		emac_xfer = "/pinctrl/emac/emac-xfer";
		emac_mdio = "/pinctrl/emac/emac-mdio";
		i2c0_xfer = "/pinctrl/i2c0/i2c0-xfer";
		i2c1_xfer = "/pinctrl/i2c1/i2c1-xfer";
		i2c2_xfer = "/pinctrl/i2c2/i2c2-xfer";
		i2s_bus = "/pinctrl/i2s/i2s-bus";
		i2s_mclk = "/pinctrl/i2s/i2s-mclk";
		hdmi_ctl = "/pinctrl/hdmi/hdmi-ctl";
		uart0_xfer = "/pinctrl/uart0/uart0-xfer";
		uart1_xfer = "/pinctrl/uart1/uart1-xfer";
		uart2_xfer = "/pinctrl/uart2/uart2-xfer";
		spi_txd = "/pinctrl/spi/spi-txd";
		spi_rxd = "/pinctrl/spi/spi-rxd";
		spi_clk = "/pinctrl/spi/spi-clk";
		spi_cs0 = "/pinctrl/spi/spi-cs0";
		spi_cs1 = "/pinctrl/spi/spi-cs1";
		game_keys = "/pinctrl/buttons/game-keys";
		leds = "/gpio-leds";
		vcc_sd = "/vcc-io";
		vcc_io = "/vcc-io";
		power_led = "/power-led";
		host_drv = "/host-drv";
		usb_en = "/usb-en";
		dongle_en = "/dongle-en";
		vcc_sys = "/vsys-regulator";
		xin32k = "/xin32k";
	};
};
